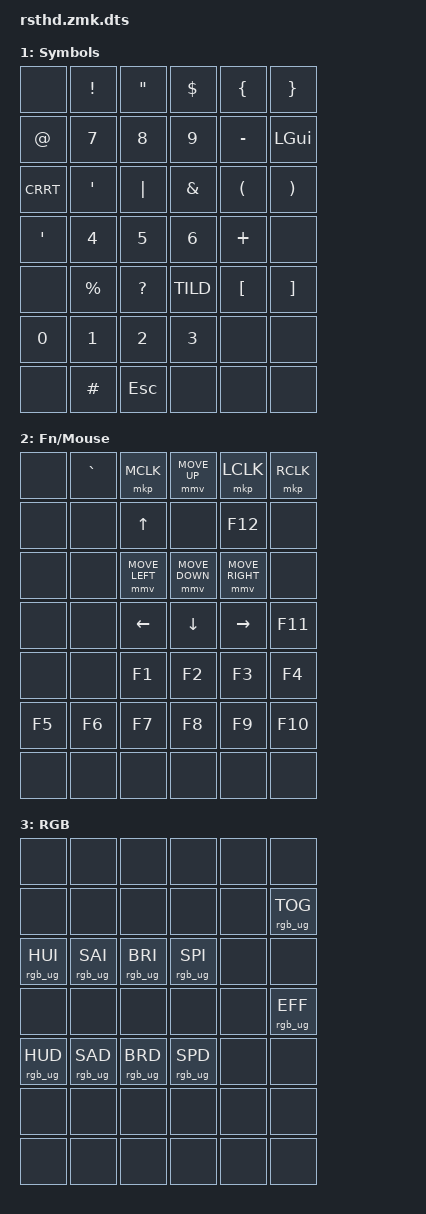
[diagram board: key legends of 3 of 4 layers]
/*
 * ZMK keymap converted from QMK config (keyboard/rsthd.json, controllerworks/mini42)
 *
 * Binding order follows the QMK LAYOUT_split_3x6_3 layout (42 positions):
 *   idx  0-5   left  row 0
 *   idx  6-11  right row 0
 *   idx 12-17  left  row 1
 *   idx 18-23  right row 1
 *   idx 24-29  left  row 2
 *   idx 30-35  right row 2
 *   idx 36-38  left  thumb cluster (3 keys)
 *   idx 39-41  right thumb cluster (3 keys)
 * The mini42 board DTS must define zmk,physical-layout in this same order.
 *
 * QMK -> ZMK mapping notes:
 *   KC_X            -> &kp X        (ZMK 0.3 keycap names, aliases in dt-bindings/zmk/keys.h)
 *   KC_NO           -> &none        (dead key, no fall-through; &trans would fall through)
 *   LT(n, KC_X)     -> &lt n X
 *   LCTL_T(KC_X)    -> &mt LCTRL X
 *   KC_BTN1/2/3     -> &mkp LCLK/MCLK/RCLK
 *   KC_MS_U/D/L/R   -> &mmv MOVE_UP/MOVE_DOWN/MOVE_LEFT/MOVE_RIGHT
 *   RGB_TOG/HUI/SAI/VAI/SPI/MOD/HUD/SAD/VAD/SPD
 *                    -> &rgb_ug RGB_TOG/HUI/SAI/BRI/SPI/EFF/HUD/SAD/BRD/SPD
 *      (QMK RGB_MOD "effect cycling" -> RGB_EFF "next effect")
 */

#include <dt-bindings/zmk/keys.h>
#include <dt-bindings/zmk/pointing.h>
#include <dt-bindings/zmk/rgb.h>
#include <behaviors.dtsi>

/ {
    keymap {
        compatible = "zmk,keymap";

        base {
            display-name = "Base";
            bindings = <
                &kp LALT   &kp J     &kp C     &kp Y     &kp F     &kp K
                &kp Z      &kp L     &kp COMMA &kp U     &kp Q     &kp EQL
                &kp LSHIFT &kp R     &kp S     &kp T     &kp H     &kp D
                &kp M      &kp N     &kp A     &kp I     &kp O     &kp RSHIFT
                &kp LGUI   &mt LCTRL SLASH &kp V    &kp G     &kp P
                &kp B      &kp X     &kp W     &kp PERIOD &kp SEMI &kp UNDER
                &kp TAB    &lt 3 E   &kp BSPC  &lt 1 ENTER &lt 2 SPC &none
            >;
        };

        symbols {
            display-name = "Symbols";
            bindings = <
                &none     &kp EXCL   &kp DQT    &kp DOLLAR &kp LBRC  &kp RBRC
                &kp AT    &kp N7     &kp N8     &kp N9     &kp MINUS &kp LGUI
                &kp CRRT  &kp QUOT   &kp PIPE   &kp AMPS   &kp LPRN  &kp RPRN
                &kp APOS  &kp N4     &kp N5     &kp N6     &kp PLUS  &none
                &none     &kp PRCNT  &kp QMARK  &kp TILD   &kp LBKT  &kp RBKT
                &kp N0    &kp N1     &kp N2     &kp N3     &none     &none
                &none     &kp POUND  &kp ESC    &none      &none     &none
            >;
        };

        fn {
            display-name = "Fn/Mouse";
            bindings = <
                &none      &kp GRAV  &mkp MCLK    &mmv MOVE_UP     &mkp LCLK  &mkp RCLK
                &none      &none     &kp UP       &none            &kp F12    &none
                &none      &none     &mmv MOVE_LEFT &mmv MOVE_DOWN &mmv MOVE_RIGHT &none
                &none      &none     &kp LEFT     &kp DOWN         &kp RIGHT  &kp F11
                &none      &none     &kp F1       &kp F2           &kp F3     &kp F4
                &kp F5     &kp F6    &kp F7       &kp F8           &kp F9     &kp F10
                &none      &none     &none        &none            &none      &none
            >;
        };

        rgb {
            display-name = "RGB";
            bindings = <
                &none     &none     &none     &none     &none     &none
                &none     &none     &none     &none     &none     &rgb_ug RGB_TOG
                &rgb_ug RGB_HUI &rgb_ug RGB_SAI &rgb_ug RGB_BRI &rgb_ug RGB_SPI &none     &none
                &none     &none     &none     &none     &none     &rgb_ug RGB_EFF
                &rgb_ug RGB_HUD &rgb_ug RGB_SAD &rgb_ug RGB_BRD &rgb_ug RGB_SPD &none     &none
                &none     &none     &none     &none     &none     &none
                &none     &none     &none     &none     &none     &none
            >;
        };
    };
};
